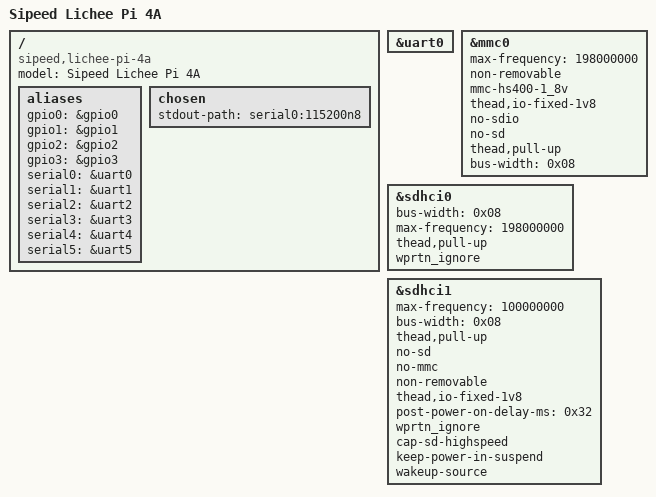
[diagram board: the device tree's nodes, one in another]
// SPDX-License-Identifier: GPL-2.0
/*
 * Copyright (C) 2023 Jisheng Zhang <jszhang@kernel.org>
 */

#include "th1520-lichee-module-4a.dtsi"

/ {
	model = "Sipeed Lichee Pi 4A";
	compatible = "sipeed,lichee-pi-4a", "sipeed,lichee-module-4a", "thead,th1520";

	aliases {
		gpio0 = &gpio0;
		gpio1 = &gpio1;
		gpio2 = &gpio2;
		gpio3 = &gpio3;
		serial0 = &uart0;
		serial1 = &uart1;
		serial2 = &uart2;
		serial3 = &uart3;
		serial4 = &uart4;
		serial5 = &uart5;
	};

	chosen {
		stdout-path = "serial0:115200n8";
	};
};

&uart0 {
	status = "okay";
};

&mmc0 {
        max-frequency = <198000000>;
        non-removable;
        mmc-hs400-1_8v;
        thead,io-fixed-1v8;
        no-sdio;
        no-sd;
        thead,pull-up;
        bus-width = <0x08>;
        status = "okay";
};

&sdhci0 {
        bus-width = <0x08>;
        max-frequency = <198000000>;
        thead,pull-up;
        wprtn_ignore;
        status = "okay";
};

&sdhci1 { 
	max-frequency = <100000000>;
        bus-width = <0x08>;
        thead,pull-up;
        no-sd;
        no-mmc;
        non-removable;
        thead,io-fixed-1v8;
        post-power-on-delay-ms = <0x32>;
        wprtn_ignore;
        cap-sd-highspeed;
        keep-power-in-suspend;
        wakeup-source;
        status = "okay";
};
